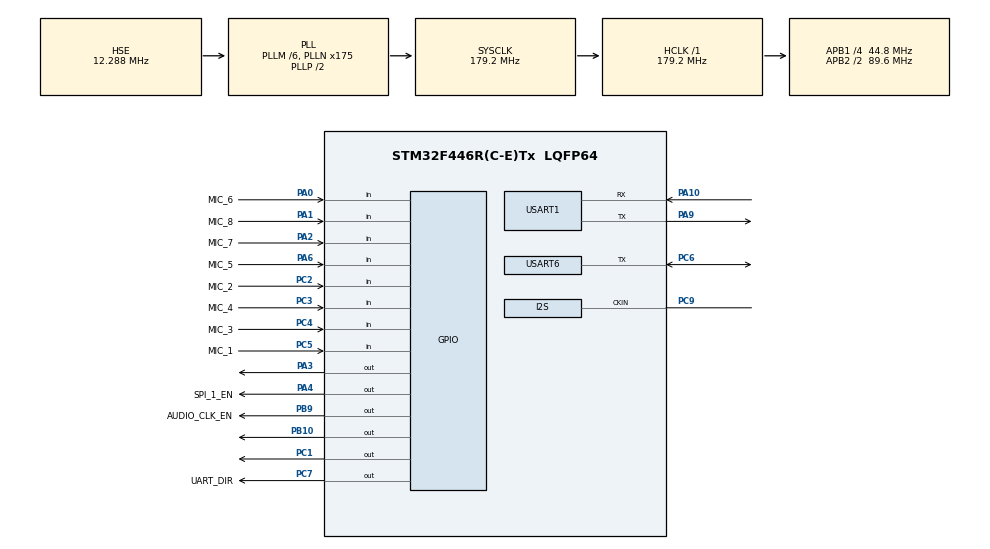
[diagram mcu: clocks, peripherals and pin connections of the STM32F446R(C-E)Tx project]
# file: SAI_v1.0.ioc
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Mcu.Family=STM32F4
Mcu.Name=STM32F446R(C-E)Tx
Mcu.Package=LQFP64
NVIC.PriorityGroup=NVIC_PRIORITYGROUP_4
PA0-WKUP.GPIO_Label=MIC_6
PA0-WKUP.Signal=GPIO_Input
PA1.GPIO_Label=MIC_8
PA1.Signal=GPIO_Input
PA10.Mode=Asynchronous
PA10.Signal=USART1_RX
PA2.GPIO_Label=MIC_7
PA2.Signal=GPIO_Input
PA3.Signal=GPIO_Output
PA4.GPIO_Label=SPI_1_EN
PA4.GPIO_Speed=GPIO_SPEED_FREQ_VERY_HIGH
PA4.Signal=GPIO_Output
PA6.GPIO_Label=MIC_5
PA6.Signal=GPIO_Input
PA9.Mode=Asynchronous
PA9.Signal=USART1_TX
PB10.Signal=GPIO_Output
PB12.Signal=SPI2_NSS
PB14.Signal=SPI2_MISO
PB15.Signal=SPI2_MOSI
PB9.GPIO_Label=AUDIO_CLK_EN
PB9.GPIO_Speed=GPIO_SPEED_FREQ_VERY_HIGH
PB9.Signal=GPIO_Output
PC1.Signal=GPIO_Output
PC14-OSC32_IN.Mode=LSE-External-Oscillator
PC14-OSC32_IN.Signal=RCC_OSC32_IN
PC15-OSC32_OUT.Mode=LSE-External-Oscillator
PC15-OSC32_OUT.Signal=RCC_OSC32_OUT
PC2.GPIO_Label=MIC_2
PC2.Signal=GPIO_Input
PC3.GPIO_Label=MIC_4
PC3.Signal=GPIO_Input
PC4.GPIO_Label=MIC_3
PC4.Signal=GPIO_Input
PC5.GPIO_Label=MIC_1
PC5.Signal=GPIO_Input
PC6.Mode=Half_duplex(single_wire_mode)
PC6.Signal=USART6_TX
PC7.GPIO_Label=UART_DIR
PC7.GPIO_Speed=GPIO_SPEED_FREQ_VERY_HIGH
PC7.Signal=GPIO_Output
PC9.GPIO_Speed=GPIO_SPEED_FREQ_VERY_HIGH
PC9.Mode=Audio_ClockIn
PC9.Signal=I2S_CKIN
PH0-OSC_IN.Mode=HSE-External-Oscillator
PH0-OSC_IN.Signal=RCC_OSC_IN
PH1-OSC_OUT.Mode=HSE-External-Oscillator
PH1-OSC_OUT.Signal=RCC_OSC_OUT
ProjectManager.HeapSize=0x200
ProjectManager.StackSize=0x400
ProjectManager.TargetToolchain=MDK-ARM V5
RCC.AHBFreq_Value=179200000
RCC.APB1CLKDivider=RCC_HCLK_DIV4
RCC.APB1Freq_Value=44800000
RCC.APB1TimFreq_Value=89600000
RCC.APB2CLKDivider=RCC_HCLK_DIV2
RCC.APB2Freq_Value=89600000
RCC.APB2TimFreq_Value=179200000
RCC.CortexFreq_Value=179200000
RCC.HCLKFreq_Value=179200000
RCC.HSE_VALUE=12288000
RCC.PLLI2SM=8
RCC.PLLI2SN=128
RCC.PLLI2SR=4
RCC.PLLM=6
RCC.PLLN=175
RCC.PLLSAIM=8
RCC.PLLSAIN=128
RCC.PLLSAIP=RCC_PLLSAIP_DIV8
RCC.PLLSAIQ=4
RCC.PLLSAIQDiv=4
RCC.PLLSourceVirtual=RCC_PLLSOURCE_HSE
RCC.SYSCLKFreq_VALUE=179200000
RCC.SYSCLKSource=RCC_SYSCLKSOURCE_PLLCLK
RCC.USBCLockSelection=RCC_CLK48CLKSOURCE_PLLSAIP
RCC.USBFreq_Value=24576000
RCC.VCOOutputFreq_Value=358400000
USART1.VirtualMode=VM_ASYNC
USART6.VirtualMode=VM_ASYNC
board=MM

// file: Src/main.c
/**
  ******************************************************************************
  * @file           : main.c
  * @brief          : Main program body
  ******************************************************************************
  ** This notice applies to any and all portions of this file
  * that are not between comment pairs USER CODE BEGIN and
  * USER CODE END. Other portions of this file, whether
  * inserted by the user or by software development tools
  * are owned by their respective copyright owners.
  *
  * COPYRIGHT(c) 2018 STMicroelectronics
  *
  * Redistribution and use in source and binary forms, with or without modification,
  * are permitted provided that the following conditions are met:
  *   1. Redistributions of source code must retain the above copyright notice,
  *      this list of conditions and the following disclaimer.
  *   2. Redistributions in binary form must reproduce the above copyright notice,
  *      this list of conditions and the following disclaimer in the documentation
  *      and/or other materials provided with the distribution.
  *   3. Neither the name of STMicroelectronics nor the names of its contributors
  *      may be used to endorse or promote products derived from this software
  *      without specific prior written permission.
  *
  * THIS SOFTWARE IS PROVIDED BY THE COPYRIGHT HOLDERS AND CONTRIBUTORS "AS IS"
  * AND ANY EXPRESS OR IMPLIED WARRANTIES, INCLUDING, BUT NOT LIMITED TO, THE
  * IMPLIED WARRANTIES OF MERCHANTABILITY AND FITNESS FOR A PARTICULAR PURPOSE ARE
  * DISCLAIMED. IN NO EVENT SHALL THE COPYRIGHT HOLDER OR CONTRIBUTORS BE LIABLE
  * FOR ANY DIRECT, INDIRECT, INCIDENTAL, SPECIAL, EXEMPLARY, OR CONSEQUENTIAL
  * DAMAGES (INCLUDING, BUT NOT LIMITED TO, PROCUREMENT OF SUBSTITUTE GOODS OR
  * SERVICES; LOSS OF USE, DATA, OR PROFITS; OR BUSINESS INTERRUPTION) HOWEVER
  * CAUSED AND ON ANY THEORY OF LIABILITY, WHETHER IN CONTRACT, STRICT LIABILITY,
  * OR TORT (INCLUDING NEGLIGENCE OR OTHERWISE) ARISING IN ANY WAY OUT OF THE USE
  * OF THIS SOFTWARE, EVEN IF ADVISED OF THE POSSIBILITY OF SUCH DAMAGE.
  *
  ******************************************************************************
  */
#include "main.h"
#include "stm32f4xx_hal.h"

UART_HandleTypeDef huart1;
UART_HandleTypeDef huart6;

/* USER CODE BEGIN PV */
/* Private variables ---------------------------------------------------------*/

/* USER CODE END PV */

void SystemClock_Config(void);
static void MX_GPIO_Init(void);
static void MX_USART1_UART_Init(void);
static void MX_USART6_UART_Init(void);

/* USER CODE BEGIN PFP */
/* Private function prototypes -----------------------------------------------*/

/* USER CODE END PFP */

int main(void)
{

  /* MCU Configuration----------------------------------------------------------*/

  /* Reset of all peripherals, Initializes the Flash interface and the Systick. */
  HAL_Init();

  /* Configure the system clock */
  SystemClock_Config();

  /* Initialize all configured peripherals */
  MX_GPIO_Init();
  MX_USART1_UART_Init();
  MX_USART6_UART_Init();
  /* USER CODE BEGIN 2 */

  HAL_UART_Transmit(&huart1, (uint8_t*)"app_start\n\r", sizeof("app_start\n\r"), 0xFFFF);

  /* USER CODE END 2 */

  /* Infinite loop */
  /* USER CODE BEGIN WHILE */
  while (1)
  {

    HAL_Delay(10);

  /* USER CODE END WHILE */

  /* USER CODE BEGIN 3 */

  HAL_GPIO_TogglePin(GPIOA, GPIO_PIN_3);
  HAL_GPIO_TogglePin(GPIOC, GPIO_PIN_1);
  HAL_GPIO_TogglePin(GPIOB, GPIO_PIN_10);

  }
  /* USER CODE END 3 */

}

void SystemClock_Config(void)
{

  RCC_OscInitTypeDef RCC_OscInitStruct;
  RCC_ClkInitTypeDef RCC_ClkInitStruct;

    /**Configure the main internal regulator output voltage
    */
  __HAL_RCC_PWR_CLK_ENABLE();

  __HAL_PWR_VOLTAGESCALING_CONFIG(PWR_REGULATOR_VOLTAGE_SCALE1);

    /**Initializes the CPU, AHB and APB busses clocks
    */
  RCC_OscInitStruct.OscillatorType = RCC_OSCILLATORTYPE_HSE;
  RCC_OscInitStruct.HSEState = RCC_HSE_ON;
  RCC_OscInitStruct.PLL.PLLState = RCC_PLL_ON;
  RCC_OscInitStruct.PLL.PLLSource = RCC_PLLSOURCE_HSE;
  RCC_OscInitStruct.PLL.PLLM = 6;
  RCC_OscInitStruct.PLL.PLLN = 175;
  RCC_OscInitStruct.PLL.PLLP = RCC_PLLP_DIV2;
  RCC_OscInitStruct.PLL.PLLQ = 2;
  RCC_OscInitStruct.PLL.PLLR = 2;
  if (HAL_RCC_OscConfig(&RCC_OscInitStruct) != HAL_OK)
  {
    _Error_Handler(__FILE__, __LINE__);
  }

    /**Activate the Over-Drive mode
    */
  if (HAL_PWREx_EnableOverDrive() != HAL_OK)
  {
    _Error_Handler(__FILE__, __LINE__);
  }

    /**Initializes the CPU, AHB and APB busses clocks
    */
  RCC_ClkInitStruct.ClockType = RCC_CLOCKTYPE_HCLK|RCC_CLOCKTYPE_SYSCLK
                              |RCC_CLOCKTYPE_PCLK1|RCC_CLOCKTYPE_PCLK2;
  RCC_ClkInitStruct.SYSCLKSource = RCC_SYSCLKSOURCE_PLLCLK;
  RCC_ClkInitStruct.AHBCLKDivider = RCC_SYSCLK_DIV1;
  RCC_ClkInitStruct.APB1CLKDivider = RCC_HCLK_DIV4;
  RCC_ClkInitStruct.APB2CLKDivider = RCC_HCLK_DIV2;

  if (HAL_RCC_ClockConfig(&RCC_ClkInitStruct, FLASH_LATENCY_5) != HAL_OK)
  {
    _Error_Handler(__FILE__, __LINE__);
  }

    /**Configure the Systick interrupt time
    */
  HAL_SYSTICK_Config(HAL_RCC_GetHCLKFreq()/1000);

    /**Configure the Systick
    */
  HAL_SYSTICK_CLKSourceConfig(SYSTICK_CLKSOURCE_HCLK);

  /* SysTick_IRQn interrupt configuration */
  HAL_NVIC_SetPriority(SysTick_IRQn, 0, 0);
}

/* USART1 init function */
static void MX_USART1_UART_Init(void)
{

  huart1.Instance = USART1;
  huart1.Init.BaudRate = 115200;
  huart1.Init.WordLength = UART_WORDLENGTH_8B;
  huart1.Init.StopBits = UART_STOPBITS_1;
  huart1.Init.Parity = UART_PARITY_NONE;
  huart1.Init.Mode = UART_MODE_TX_RX;
  huart1.Init.HwFlowCtl = UART_HWCONTROL_NONE;
  huart1.Init.OverSampling = UART_OVERSAMPLING_16;
  if (HAL_UART_Init(&huart1) != HAL_OK)
  {
    _Error_Handler(__FILE__, __LINE__);
  }

}

/* USART6 init function */
static void MX_USART6_UART_Init(void)
{

  huart6.Instance = USART6;
  huart6.Init.BaudRate = 115200;
  huart6.Init.WordLength = UART_WORDLENGTH_8B;
  huart6.Init.StopBits = UART_STOPBITS_1;
  huart6.Init.Parity = UART_PARITY_NONE;
  huart6.Init.Mode = UART_MODE_TX_RX;
  huart6.Init.HwFlowCtl = UART_HWCONTROL_NONE;
  huart6.Init.OverSampling = UART_OVERSAMPLING_16;
  if (HAL_HalfDuplex_Init(&huart6) != HAL_OK)
  {
    _Error_Handler(__FILE__, __LINE__);
  }

}

/** Configure pins as
        * Analog
        * Input
        * Output
        * EVENT_OUT
        * EXTI
     PB12   ------> SPI2_NSS
     PB14   ------> SPI2_MISO
     PB15   ------> SPI2_MOSI
     PC9   ------> I2S_CKIN
*/
static void MX_GPIO_Init(void)
{

  GPIO_InitTypeDef GPIO_InitStruct;

  /* GPIO Ports Clock Enable */
  __HAL_RCC_GPIOC_CLK_ENABLE();
  __HAL_RCC_GPIOH_CLK_ENABLE();
  __HAL_RCC_GPIOA_CLK_ENABLE();
  __HAL_RCC_GPIOB_CLK_ENABLE();

  /*Configure GPIO pin Output Level */
  HAL_GPIO_WritePin(GPIOC, GPIO_PIN_1|UART_DIR_Pin, GPIO_PIN_RESET);

  /*Configure GPIO pin Output Level */
  HAL_GPIO_WritePin(GPIOA, GPIO_PIN_3|SPI_1_EN_Pin, GPIO_PIN_RESET);

  /*Configure GPIO pin Output Level */
  HAL_GPIO_WritePin(GPIOB, GPIO_PIN_10|AUDIO_CLK_EN_Pin, GPIO_PIN_RESET);

  /*Configure GPIO pin : PC1 */
  GPIO_InitStruct.Pin = GPIO_PIN_1;
  GPIO_InitStruct.Mode = GPIO_MODE_OUTPUT_PP;
  GPIO_InitStruct.Pull = GPIO_NOPULL;
  GPIO_InitStruct.Speed = GPIO_SPEED_FREQ_LOW;
  HAL_GPIO_Init(GPIOC, &GPIO_InitStruct);

  /*Configure GPIO pins : MIC_2_Pin MIC_4_Pin MIC_3_Pin MIC_1_Pin */
  GPIO_InitStruct.Pin = MIC_2_Pin|MIC_4_Pin|MIC_3_Pin|MIC_1_Pin;
  GPIO_InitStruct.Mode = GPIO_MODE_INPUT;
  GPIO_InitStruct.Pull = GPIO_NOPULL;
  HAL_GPIO_Init(GPIOC, &GPIO_InitStruct);

  /*Configure GPIO pins : MIC_6_Pin MIC_8_Pin MIC_7_Pin MIC_5_Pin */
  GPIO_InitStruct.Pin = MIC_6_Pin|MIC_8_Pin|MIC_7_Pin|MIC_5_Pin;
  GPIO_InitStruct.Mode = GPIO_MODE_INPUT;
  GPIO_InitStruct.Pull = GPIO_NOPULL;
  HAL_GPIO_Init(GPIOA, &GPIO_InitStruct);

  /*Configure GPIO pin : PA3 */
  GPIO_InitStruct.Pin = GPIO_PIN_3;
  GPIO_InitStruct.Mode = GPIO_MODE_OUTPUT_PP;
  GPIO_InitStruct.Pull = GPIO_NOPULL;
  GPIO_InitStruct.Speed = GPIO_SPEED_FREQ_LOW;
  HAL_GPIO_Init(GPIOA, &GPIO_InitStruct);

  /*Configure GPIO pin : SPI_1_EN_Pin */
  GPIO_InitStruct.Pin = SPI_1_EN_Pin;
  GPIO_InitStruct.Mode = GPIO_MODE_OUTPUT_PP;
  GPIO_InitStruct.Pull = GPIO_NOPULL;
  GPIO_InitStruct.Speed = GPIO_SPEED_FREQ_VERY_HIGH;
  HAL_GPIO_Init(SPI_1_EN_GPIO_Port, &GPIO_InitStruct);

  /*Configure GPIO pin : PB10 */
  GPIO_InitStruct.Pin = GPIO_PIN_10;
  GPIO_InitStruct.Mode = GPIO_MODE_OUTPUT_PP;
  GPIO_InitStruct.Pull = GPIO_NOPULL;
  GPIO_InitStruct.Speed = GPIO_SPEED_FREQ_LOW;
  HAL_GPIO_Init(GPIOB, &GPIO_InitStruct);

  /*Configure GPIO pins : PB12 PB14 PB15 */
  GPIO_InitStruct.Pin = GPIO_PIN_12|GPIO_PIN_14|GPIO_PIN_15;
  GPIO_InitStruct.Mode = GPIO_MODE_AF_PP;
  GPIO_InitStruct.Pull = GPIO_NOPULL;
  GPIO_InitStruct.Speed = GPIO_SPEED_FREQ_VERY_HIGH;
  GPIO_InitStruct.Alternate = GPIO_AF5_SPI2;
  HAL_GPIO_Init(GPIOB, &GPIO_InitStruct);

  /*Configure GPIO pin : UART_DIR_Pin */
  GPIO_InitStruct.Pin = UART_DIR_Pin;
  GPIO_InitStruct.Mode = GPIO_MODE_OUTPUT_PP;
  GPIO_InitStruct.Pull = GPIO_NOPULL;
  GPIO_InitStruct.Speed = GPIO_SPEED_FREQ_VERY_HIGH;
  HAL_GPIO_Init(UART_DIR_GPIO_Port, &GPIO_InitStruct);

  /*Configure GPIO pin : PC9 */
  GPIO_InitStruct.Pin = GPIO_PIN_9;
  GPIO_InitStruct.Mode = GPIO_MODE_AF_PP;
  GPIO_InitStruct.Pull = GPIO_NOPULL;
  GPIO_InitStruct.Speed = GPIO_SPEED_FREQ_VERY_HIGH;
  GPIO_InitStruct.Alternate = GPIO_AF5_SPI1;
  HAL_GPIO_Init(GPIOC, &GPIO_InitStruct);

  /*Configure GPIO pin : AUDIO_CLK_EN_Pin */
  GPIO_InitStruct.Pin = AUDIO_CLK_EN_Pin;
  GPIO_InitStruct.Mode = GPIO_MODE_OUTPUT_PP;
  GPIO_InitStruct.Pull = GPIO_NOPULL;
  GPIO_InitStruct.Speed = GPIO_SPEED_FREQ_VERY_HIGH;
  HAL_GPIO_Init(AUDIO_CLK_EN_GPIO_Port, &GPIO_InitStruct);

}

void _Error_Handler(char *file, int line)
{
  while(1)
  {
  }
}

/************************ (C) COPYRIGHT STMicroelectronics *****END OF FILE****/
